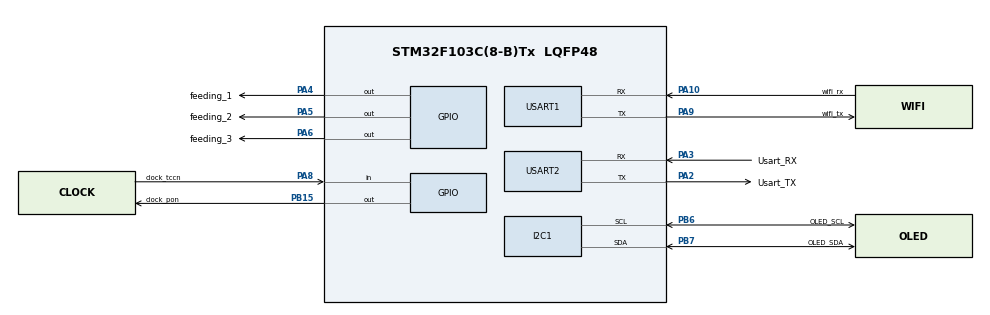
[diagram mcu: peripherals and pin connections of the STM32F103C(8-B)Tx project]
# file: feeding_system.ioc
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Mcu.Family=STM32F1
Mcu.Name=STM32F103C(8-B)Tx
Mcu.Package=LQFP48
NVIC.PriorityGroup=NVIC_PRIORITYGROUP_4
NVIC.USART1_IRQn=true\:0\:0\:false\:false\:true\:false\:true\:true\:true
NVIC.USART2_IRQn=true\:0\:0\:false\:false\:true\:false\:true\:true\:true
PA10.GPIO_Label=wifi_rx
PA10.Mode=Asynchronous
PA10.Signal=USART1_RX
PA13.Mode=Serial_Wire
PA13.Signal=SYS_JTMS-SWDIO
PA14.Mode=Serial_Wire
PA14.Signal=SYS_JTCK-SWCLK
PA2.GPIO_Label=Usart_TX
PA2.Mode=Asynchronous
PA2.Signal=USART2_TX
PA3.GPIO_Label=Usart_RX
PA3.Mode=Asynchronous
PA3.Signal=USART2_RX
PA4.GPIO_Label=feeding_1
PA4.Signal=GPIO_Output
PA5.GPIO_Label=feeding_2
PA5.Signal=GPIO_Output
PA6.GPIO_Label=feeding_3
PA6.Signal=GPIO_Output
PA8.GPIO_Label=clock_tccn
PA8.Signal=GPIO_Input
PA9.GPIO_Label=wifi_tx
PA9.Mode=Asynchronous
PA9.Signal=USART1_TX
PB15.GPIO_Label=clock_pon
PB15.Signal=GPIO_Output
PB6.GPIO_Label=OLED_SCL
PB6.Mode=I2C
PB6.Signal=I2C1_SCL
PB7.GPIO_Label=OLED_SDA
PB7.Mode=I2C
PB7.Signal=I2C1_SDA
ProjectManager.HeapSize=0x200
ProjectManager.StackSize=0x400
ProjectManager.TargetToolchain=MDK-ARM V5.32
RCC.APB1Freq_Value=8000000
RCC.APB2Freq_Value=8000000
RealThread.RT-Thread.3.1.5.RTOSJjkernel=true
RealThread.RT-Thread.3.1.5.RTOSJjshell=true
USART1.VirtualMode=VM_ASYNC
USART2.VirtualMode=VM_ASYNC
VP_RealThread.RT-Thread_VS_RTOSJjkernel_3.1.5_3.1.5.Mode=RTOSJjkernel
VP_RealThread.RT-Thread_VS_RTOSJjshell_3.1.5_3.1.5.Mode=RTOSJjshell
board=custom

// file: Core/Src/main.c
/* USER CODE BEGIN Header */
/**
  ******************************************************************************
  * @file           : main.c
  * @brief          : Main program body
  ******************************************************************************
  * @attention
  *
  * Copyright (c) 2023 STMicroelectronics.
  * All rights reserved.
  *
  * This software is licensed under terms that can be found in the LICENSE file
  * in the root directory of this software component.
  * If no LICENSE file comes with this software, it is provided AS-IS.
  *
  ******************************************************************************
  */
/* USER CODE END Header */

#include "main.h"
#include "i2c.h"
#include "usart.h"
#include "gpio.h"

/* USER CODE BEGIN Includes */
#include <rtthread.h>
#include "stdio.h"
#include "string.h"
#include "stdlib.h"
#include "data_structure.h"
#include "timer.h"
/* USER CODE END Includes */

/* USER CODE BEGIN PV */
#define BUFFER_SIZE 200
/* USER CODE END PV */

void SystemClock_Config(void);

/* USER CODE BEGIN 0 */
#define BUFFER_SIZE 200
void InitTIMER();
/* USER CODE END 0 */

int main(void)
{

  /* MCU Configuration--------------------------------------------------------*/

  /* Reset of all peripherals, Initializes the Flash interface and the Systick. */
  HAL_Init();

  /* Configure the system clock */
  SystemClock_Config();

  /* Initialize all configured peripherals */
  MX_GPIO_Init();
  MX_I2C1_Init();
  MX_USART1_UART_Init();
  MX_USART2_UART_Init();

        int *device_status = (int *)malloc(2 * sizeof(int));
        InitTIMER();
  /* Infinite loop */
  while (1)
  {

      rt_kprintf("Current date: %d-%02d-%02d, %02d:%02d:%02d\n{", getTimerDate()->year, getTimerDate()->month, getTimerDate()->day, getTimerTime()->h, getTimerTime()->m, getTimerTime()->s);

      int result=timerRun(2,device_status);
      rt_kprintf("result:%d\n",result);
      for (int j = 0; j < 2; j++) {
            rt_kprintf("%d,", device_status[j]);
        }

        rt_kprintf("}\n");
      rt_thread_mdelay(1000);
  }
}

void SystemClock_Config(void)
{
  RCC_OscInitTypeDef RCC_OscInitStruct = {0};
  RCC_ClkInitTypeDef RCC_ClkInitStruct = {0};

  /** Initializes the RCC Oscillators according to the specified parameters
  * in the RCC_OscInitTypeDef structure.
  */
  RCC_OscInitStruct.OscillatorType = RCC_OSCILLATORTYPE_HSI;
  RCC_OscInitStruct.HSIState = RCC_HSI_ON;
  RCC_OscInitStruct.HSICalibrationValue = RCC_HSICALIBRATION_DEFAULT;
  RCC_OscInitStruct.PLL.PLLState = RCC_PLL_NONE;
  if (HAL_RCC_OscConfig(&RCC_OscInitStruct) != HAL_OK)
  {
    Error_Handler();
  }

  /** Initializes the CPU, AHB and APB buses clocks
  */
  RCC_ClkInitStruct.ClockType = RCC_CLOCKTYPE_HCLK|RCC_CLOCKTYPE_SYSCLK
                              |RCC_CLOCKTYPE_PCLK1|RCC_CLOCKTYPE_PCLK2;
  RCC_ClkInitStruct.SYSCLKSource = RCC_SYSCLKSOURCE_HSI;
  RCC_ClkInitStruct.AHBCLKDivider = RCC_SYSCLK_DIV1;
  RCC_ClkInitStruct.APB1CLKDivider = RCC_HCLK_DIV1;
  RCC_ClkInitStruct.APB2CLKDivider = RCC_HCLK_DIV1;

  if (HAL_RCC_ClockConfig(&RCC_ClkInitStruct, FLASH_LATENCY_0) != HAL_OK)
  {
    Error_Handler();
  }
}

void InitTIMER()
{
  rt_kprintf( "InitTIMER\n");
  Date *date_ = newDate(2023, 6, 1);
  Time *time_ = newTime(12, 4, 30);
  // 创建一些测试计划
    Plan* plans = NULL;
insertPlan(&plans, 1, 1, *newTime(12, 5, 0), 10, *newDate(2023, 1, 1), *newDate(2023, 12, 31));
insertPlan(&plans, 2, 2, *newTime(13, 5, 0), 10, *newDate(2023, 6, 1), *newDate(2023, 6, 30));
rt_kprintf("Plan1: beginDate:%d-%d-%d,endDate:%d-%d-%d,time:%d:%d:%d\n", plans[0].beginDate.year, plans[0].beginDate.month, plans[0].beginDate.day,plans[0].endDate.year, plans[0].endDate.month, plans[0].endDate.day ,plans[0].time.h, plans[0].time.m,plans[0].time.s);
rt_kprintf("Plan2: beginDate:%d-%d-%d,endDate:%d-%d-%d,time:%d:%d:%d\n", plans[1].beginDate.year, plans[1].beginDate.month, plans[1].beginDate.day,plans[1].endDate.year, plans[1].endDate.month, plans[1].endDate.day ,plans[1].time.h, plans[1].time.m,plans[1].time.s);
rt_kprintf("timerInit\n");
timerInit(date_, time_, plans);  // 传递计划的数量
rt_kprintf("timerInit_ok\n");
free(plans);
}
/* USER CODE END 4 */

void Error_Handler(void)
{
  __disable_irq();
  while (1)
  {
  }
}
